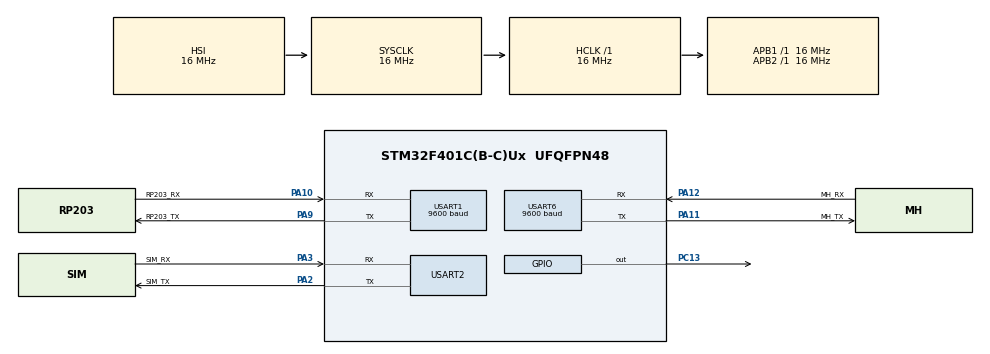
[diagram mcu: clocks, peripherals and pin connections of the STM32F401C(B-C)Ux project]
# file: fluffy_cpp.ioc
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Dma.Request0=USART6_RX
Dma.USART6_RX.0.Direction=DMA_PERIPH_TO_MEMORY
Dma.USART6_RX.0.FIFOMode=DMA_FIFOMODE_DISABLE
Dma.USART6_RX.0.Instance=DMA2_Stream1
Dma.USART6_RX.0.MemDataAlignment=DMA_MDATAALIGN_BYTE
Dma.USART6_RX.0.MemInc=DMA_MINC_ENABLE
Dma.USART6_RX.0.Mode=DMA_NORMAL
Dma.USART6_RX.0.PeriphDataAlignment=DMA_PDATAALIGN_BYTE
Dma.USART6_RX.0.PeriphInc=DMA_PINC_DISABLE
Dma.USART6_RX.0.Priority=DMA_PRIORITY_LOW
FREERTOS.Tasks01=defaultTask,24,128,StartDefaultTask,Default,NULL,Dynamic,NULL,NULL
Mcu.Family=STM32F4
Mcu.Name=STM32F401C(B-C)Ux
Mcu.Package=UFQFPN48
NVIC.DMA2_Stream1_IRQn=true\:5\:0\:false\:false\:true\:true\:false\:true\:true
NVIC.PriorityGroup=NVIC_PRIORITYGROUP_4
NVIC.USART6_IRQn=true\:5\:0\:false\:false\:true\:true\:true\:true\:true
PA10.GPIO_Label=RP203_RX
PA10.Mode=Asynchronous
PA10.Signal=USART1_RX
PA11.GPIO_Label=MH_TX
PA11.Mode=Asynchronous
PA11.Signal=USART6_TX
PA12.GPIO_Label=MH_RX
PA12.Mode=Asynchronous
PA12.Signal=USART6_RX
PA13.Mode=Serial_Wire
PA13.Signal=SYS_JTMS-SWDIO
PA14.Mode=Serial_Wire
PA14.Signal=SYS_JTCK-SWCLK
PA2.GPIO_Label=SIM_TX
PA2.Mode=Asynchronous
PA2.Signal=USART2_TX
PA3.GPIO_Label=SIM_RX
PA3.Mode=Asynchronous
PA3.Signal=USART2_RX
PA9.GPIO_Label=RP203_TX
PA9.Mode=Asynchronous
PA9.Signal=USART1_TX
PC13-ANTI_TAMP.Signal=GPIO_Output
ProjectManager.HeapSize=0x200
ProjectManager.StackSize=0x400
ProjectManager.TargetToolchain=STM32CubeIDE
RCC.AHBFreq_Value=16000000
RCC.APB1Freq_Value=16000000
RCC.APB2Freq_Value=16000000
RCC.CortexFreq_Value=16000000
RCC.HSE_VALUE=25000000
RCC.HSI_VALUE=16000000
RCC.LSE_VALUE=32768
RCC.SYSCLKFreq_VALUE=16000000
RCC.VCOOutputFreq_Value=192000000
USART1.BaudRate=9600
USART1.VirtualMode=VM_ASYNC
USART2.VirtualMode=VM_ASYNC
USART6.BaudRate=9600
USART6.VirtualMode=VM_ASYNC
VP_FREERTOS_VS_CMSIS_V2.Mode=CMSIS_V2
board=custom

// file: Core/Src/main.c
/* USER CODE BEGIN Header */
/**
  ******************************************************************************
  * @file           : main.c
  * @brief          : Main program body
  ******************************************************************************
  * @attention
  *
  * Copyright (c) 2023 STMicroelectronics.
  * All rights reserved.
  *
  * This software is licensed under terms that can be found in the LICENSE file
  * in the root directory of this software component.
  * If no LICENSE file comes with this software, it is provided AS-IS.
  *
  ******************************************************************************
  */
/* USER CODE END Header */
#include "main.h"
#include "cmsis_os.h"

uint8_t UART6_rxBuffer[20] = {0};
uint8_t received = 0;

UART_HandleTypeDef huart1;
UART_HandleTypeDef huart2;
UART_HandleTypeDef huart6;
DMA_HandleTypeDef hdma_usart6_rx;

/* Definitions for defaultTask */
osThreadId_t defaultTaskHandle;
const osThreadAttr_t defaultTask_attributes = {
  .name = "defaultTask",
  .stack_size = 128 * 4,
  .priority = (osPriority_t) osPriorityNormal,
};

void SystemClock_Config(void);
static void MX_GPIO_Init(void);
static void MX_DMA_Init(void);
static void MX_USART1_UART_Init(void);
static void MX_USART2_UART_Init(void);
static void MX_USART6_UART_Init(void);
void StartDefaultTask(void *argument);

int main(void)
{

  /* MCU Configuration--------------------------------------------------------*/

  /* Reset of all peripherals, Initializes the Flash interface and the Systick. */
  HAL_Init();

  /* Configure the system clock */
  SystemClock_Config();

  /* Initialize all configured peripherals */
  MX_GPIO_Init();
  MX_DMA_Init();
  MX_USART1_UART_Init();
  MX_USART2_UART_Init();
  MX_USART6_UART_Init();

  /* Init scheduler */
  osKernelInitialize();

  /* Create the thread(s) */
  /* creation of defaultTask */
  defaultTaskHandle = osThreadNew(StartDefaultTask, NULL, &defaultTask_attributes);

  /* Start scheduler */
  osKernelStart();

  /* We should never get here as control is now taken by the scheduler */
  /* Infinite loop */
  while (1)
  {

  }
}

void SystemClock_Config(void)
{
  RCC_OscInitTypeDef RCC_OscInitStruct = {0};
  RCC_ClkInitTypeDef RCC_ClkInitStruct = {0};

  /** Configure the main internal regulator output voltage
  */
  __HAL_RCC_PWR_CLK_ENABLE();
  __HAL_PWR_VOLTAGESCALING_CONFIG(PWR_REGULATOR_VOLTAGE_SCALE2);

  /** Initializes the RCC Oscillators according to the specified parameters
  * in the RCC_OscInitTypeDef structure.
  */
  RCC_OscInitStruct.OscillatorType = RCC_OSCILLATORTYPE_HSI;
  RCC_OscInitStruct.HSIState = RCC_HSI_ON;
  RCC_OscInitStruct.HSICalibrationValue = RCC_HSICALIBRATION_DEFAULT;
  RCC_OscInitStruct.PLL.PLLState = RCC_PLL_NONE;
  if (HAL_RCC_OscConfig(&RCC_OscInitStruct) != HAL_OK)
  {
    Error_Handler();
  }

  /** Initializes the CPU, AHB and APB buses clocks
  */
  RCC_ClkInitStruct.ClockType = RCC_CLOCKTYPE_HCLK|RCC_CLOCKTYPE_SYSCLK
                              |RCC_CLOCKTYPE_PCLK1|RCC_CLOCKTYPE_PCLK2;
  RCC_ClkInitStruct.SYSCLKSource = RCC_SYSCLKSOURCE_HSI;
  RCC_ClkInitStruct.AHBCLKDivider = RCC_SYSCLK_DIV1;
  RCC_ClkInitStruct.APB1CLKDivider = RCC_HCLK_DIV1;
  RCC_ClkInitStruct.APB2CLKDivider = RCC_HCLK_DIV1;

  if (HAL_RCC_ClockConfig(&RCC_ClkInitStruct, FLASH_LATENCY_0) != HAL_OK)
  {
    Error_Handler();
  }
}

static void MX_USART1_UART_Init(void)
{

  huart1.Instance = USART1;
  huart1.Init.BaudRate = 9600;
  huart1.Init.WordLength = UART_WORDLENGTH_8B;
  huart1.Init.StopBits = UART_STOPBITS_1;
  huart1.Init.Parity = UART_PARITY_NONE;
  huart1.Init.Mode = UART_MODE_TX_RX;
  huart1.Init.HwFlowCtl = UART_HWCONTROL_NONE;
  huart1.Init.OverSampling = UART_OVERSAMPLING_16;
  if (HAL_UART_Init(&huart1) != HAL_OK)
  {
    Error_Handler();
  }

}

static void MX_USART2_UART_Init(void)
{

  huart2.Instance = USART2;
  huart2.Init.BaudRate = 115200;
  huart2.Init.WordLength = UART_WORDLENGTH_8B;
  huart2.Init.StopBits = UART_STOPBITS_1;
  huart2.Init.Parity = UART_PARITY_NONE;
  huart2.Init.Mode = UART_MODE_TX_RX;
  huart2.Init.HwFlowCtl = UART_HWCONTROL_NONE;
  huart2.Init.OverSampling = UART_OVERSAMPLING_16;
  if (HAL_UART_Init(&huart2) != HAL_OK)
  {
    Error_Handler();
  }

}

static void MX_USART6_UART_Init(void)
{

  huart6.Instance = USART6;
  huart6.Init.BaudRate = 9600;
  huart6.Init.WordLength = UART_WORDLENGTH_8B;
  huart6.Init.StopBits = UART_STOPBITS_1;
  huart6.Init.Parity = UART_PARITY_NONE;
  huart6.Init.Mode = UART_MODE_TX_RX;
  huart6.Init.HwFlowCtl = UART_HWCONTROL_NONE;
  huart6.Init.OverSampling = UART_OVERSAMPLING_16;
  if (HAL_UART_Init(&huart6) != HAL_OK)
  {
    Error_Handler();
  }

}

static void MX_DMA_Init(void)
{

  /* DMA controller clock enable */
  __HAL_RCC_DMA2_CLK_ENABLE();

  /* DMA interrupt init */
  /* DMA2_Stream1_IRQn interrupt configuration */
  HAL_NVIC_SetPriority(DMA2_Stream1_IRQn, 5, 0);
  HAL_NVIC_EnableIRQ(DMA2_Stream1_IRQn);

}

static void MX_GPIO_Init(void)
{
  GPIO_InitTypeDef GPIO_InitStruct = {0};

  /* GPIO Ports Clock Enable */
  __HAL_RCC_GPIOC_CLK_ENABLE();
  __HAL_RCC_GPIOA_CLK_ENABLE();

  /*Configure GPIO pin Output Level */
  HAL_GPIO_WritePin(GPIOC, GPIO_PIN_13, GPIO_PIN_RESET);

  /*Configure GPIO pin : PC13 */
  GPIO_InitStruct.Pin = GPIO_PIN_13;
  GPIO_InitStruct.Mode = GPIO_MODE_OUTPUT_PP;
  GPIO_InitStruct.Pull = GPIO_NOPULL;
  GPIO_InitStruct.Speed = GPIO_SPEED_FREQ_LOW;
  HAL_GPIO_Init(GPIOC, &GPIO_InitStruct);

}

/* USER CODE BEGIN 4 */

char serialBuffer[100];
int serialBufferLength;

void HAL_UART_RxCpltCallback(UART_HandleTypeDef *huart)
{
    //HAL_UART_Transmit(&huart1, UART1_rxBuffer, 12, 100);
    //HAL_UART_Receive_DMA(&huart1, UART1_rxBuffer, 12);

	received =1;
}

/* USER CODE END 4 */

void StartDefaultTask(void *argument)
{
  /* USER CODE BEGIN 5 */
	HAL_UART_Receive_DMA (&huart6, UART6_rxBuffer, 20);
	HAL_GPIO_WritePin(GPIOC, GPIO_PIN_13, GPIO_PIN_SET);
  /* Infinite loop */
  for(;;)
  {
	osDelay(5000);
	HAL_GPIO_TogglePin(GPIOC, GPIO_PIN_13);
	//serialBufferLength = sprintf(serialBuffer, "Hello World\r\n");
	//HAL_UART_Transmit(&huart2, serialBuffer, serialBufferLength, 100);
  }
  /* USER CODE END 5 */
}

void Error_Handler(void)
{
  __disable_irq();
  while (1)
  {
  }
}
